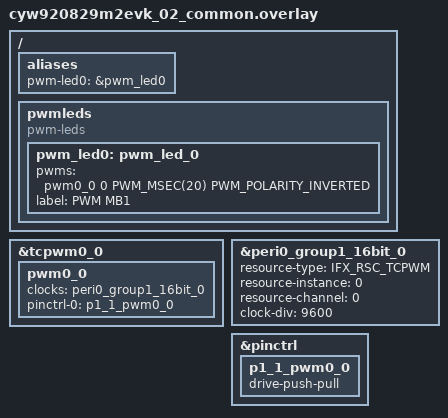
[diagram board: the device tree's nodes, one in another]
/*
 * Copyright (c) 2025 Infineon Technologies AG,
 * or an affiliate of Infineon Technologies AG.
 *
 * SPDX-License-Identifier: Apache-2.0
 */

#include <zephyr/dt-bindings/pwm/pwm.h>
#include <zephyr/dt-bindings/pwm/pwm_ifx_tcpwm.h>

/ {
	aliases {
		pwm-led0 = &pwm_led0;
	};

	pwmleds {
		compatible = "pwm-leds";

		pwm_led0: pwm_led_0 {
			pwms = <&pwm0_0 0 PWM_MSEC(20) PWM_POLARITY_INVERTED>;
			label = "PWM MB1";
		};
	};
};

&tcpwm0_0 {
	status = "okay";

	pwm0_0: pwm0_0 {
		status = "okay";
		clocks = <&peri0_group1_16bit_0>;
		pinctrl-0 = <&p1_1_pwm0_0>;
		pinctrl-names = "default";
	};
};

&peri0_group1_16bit_0 {
	status = "okay";
	resource-type = <IFX_RSC_TCPWM>;
	resource-instance = <0>;
	resource-channel = <0>;
	clock-div = <9600>;
};

&pinctrl {
	p1_1_pwm0_0: p1_1_pwm0_0 {
		drive-push-pull;
	};
};
